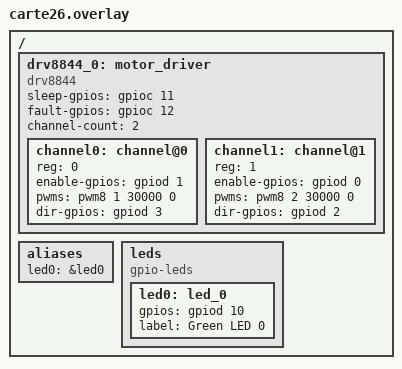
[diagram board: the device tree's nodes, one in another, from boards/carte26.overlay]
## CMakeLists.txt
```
cmake_minimum_required(VERSION 3.13.0)
find_package(Zephyr REQUIRED HINTS $ENV{ZEPHYR_BASE})

project(app LANGUAGES C CXX)
target_sources(app PRIVATE
        src/main.cpp
)
target_include_directories(
        app
        PRIVATE
        include
)
```

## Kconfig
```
# Copyright (c) 2021 Nordic Semiconductor ASA
# SPDX-License-Identifier: Apache-2.0
#
# This file is the application Kconfig entry point. All application Kconfig
# options can be defined here or included via other application Kconfig files.
# You can browse these options using the west targets menuconfig (terminal) or
# guiconfig (GUI).

menu "Zephyr"
source "Kconfig.zephyr"
endmenu

module = APP
module-str = APP
source "subsys/logging/Kconfig.template.log_config"
```

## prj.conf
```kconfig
CONFIG_DRV8876=y
CONFIG_DRV8844=y
CONFIG_PWM=y
CONFIG_CPP=y
CONFIG_STD_CPP20=y
CONFIG_LOG=y
CONFIG_CONSOLE=y
CONFIG_UART_CONSOLE=y
CONFIG_LOG_BACKEND_UART=y
CONFIG_SERIAL=y
CONFIG_LOG_DEFAULT_LEVEL=3
```

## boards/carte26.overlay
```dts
/*
	Created by Awing on the 22/10/2026
	SPDX-License-Identifier: AGPL-3.0
*/

/ {

	drv8844_0: motor_driver {
		compatible = "drv8844";
		status = "okay";

		#address-cells = <1>;
		#size-cells = <0>;

		sleep-gpios = <&gpioc 11 GPIO_ACTIVE_HIGH>;
		fault-gpios = <&gpioc 12 GPIO_ACTIVE_HIGH>;

		channel-count = <2>;

		channel0: channel@0 {
			reg = <0>;
			enable-gpios = <&gpiod 1 GPIO_ACTIVE_HIGH>;
			pwms = <&pwm8 1 30000 0>;
			dir-gpios = <&gpiod 3 GPIO_ACTIVE_HIGH>;
		};

		channel1: channel@1 {
			reg = <1>;
			enable-gpios = <&gpiod 0 GPIO_ACTIVE_HIGH>;
			pwms = <&pwm8 2 30000 0>;
			dir-gpios = <&gpiod 2 GPIO_ACTIVE_HIGH>;
		};

	};

	aliases {
		led0 = &led0;
	};

	leds {
		compatible = "gpio-leds";

		led0: led_0 {
			gpios = <&gpiod 10 GPIO_ACTIVE_HIGH>;
			label = "Green LED 0";
		};
	};

};
```

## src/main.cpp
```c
//
// Created by awing on 10/22/26.
// SPDX-License-Identifier: AGPL-3.0
//


#include <stdio.h>
#include <zephyr/kernel.h>
#include <drivers/crir-motors.h>
#include <zephyr/drivers/gpio.h>
#include <zephyr/logging/log.h>

LOG_MODULE_REGISTER(MAIN, CONFIG_LOG_DEFAULT_LEVEL);

/* 1000 msec = 1 sec */
#define SLEEP_TIME_MS   1000

/* The devicetree node identifier for the "led0" alias. */
#define LED0_NODE DT_ALIAS(led0)

static const struct device * const drv8844 = DEVICE_DT_GET(DT_NODELABEL(drv8844_0));
static const struct gpio_dt_spec led = GPIO_DT_SPEC_GET(LED0_NODE, gpios);

int main() {
    k_sleep(Z_TIMEOUT_MS(1000));
    printk("Starting...");
    if (!device_is_ready(drv8844)) {
        LOG_ERR("DRV8844 is not ready");
        return -1;
    }
    bool led_state = true;

    if (!gpio_is_ready_dt(&led)) {
        return 0;
    }

    int ret = gpio_pin_configure_dt(&led, GPIO_OUTPUT_ACTIVE);
    if (ret < 0) {
        return 0;
    }


    int n = 0;
    while (true) {
        //crir_motors_set_speed(drv8844, 0, static_cast<float>(n) / 10);
        //n++;
        //n %= 11;
        printk("Set speed to %d", n);
        //k_sleep(Z_TIMEOUT_MS(1000));
        ret = gpio_pin_toggle_dt(&led);
        if (ret < 0) {
            return 0;
        }

        led_state = !led_state;
        printf("LED state: %s\n", led_state ? "ON" : "OFF");
        k_sleep(Z_TIMEOUT_MS(1000));
    }

    return 0;
}
```

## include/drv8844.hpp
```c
#pragma once

#include <zephyr/drivers/gpio.h>
#include <zephyr/drivers/pwm.h>

struct Drv8844Motor {
    pwm_dt_spec enable;
    gpio_dt_spec input_a;
    gpio_dt_spec input_b;
};

class Drv8844 {
public:
    Drv8844(const Drv8844Motor& left, const Drv8844Motor& right,
            const gpio_dt_spec& reset, const gpio_dt_spec& fault);

    int init();
    int setVelocity(float left, float right);
    int stop();
    int readFault(bool& faulted) const;

private:
    int setMotor(const Drv8844Motor& motor, float velocity);

    Drv8844Motor left_;
    Drv8844Motor right_;
    gpio_dt_spec reset_;
    gpio_dt_spec fault_;
};
```

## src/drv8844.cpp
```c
#include "drv8844.hpp"

#include <errno.h>

#include <zephyr/device.h>
#include <zephyr/kernel.h>

namespace {
constexpr uint32_t kPwmPeriod = PWM_USEC(50);

bool gpioReady(const gpio_dt_spec& gpio)
{
    return gpio.port != nullptr && device_is_ready(gpio.port);
}
} // namespace

Drv8844::Drv8844(const Drv8844Motor& left, const Drv8844Motor& right,
                 const gpio_dt_spec& reset, const gpio_dt_spec& fault)
    : left_(left), right_(right), reset_(reset), fault_(fault)
{
}

int Drv8844::init()
{
    if (!device_is_ready(left_.enable.dev) ||
        !device_is_ready(right_.enable.dev) ||
        !gpioReady(left_.input_a) || !gpioReady(left_.input_b) ||
        !gpioReady(right_.input_a) || !gpioReady(right_.input_b) ||
        !gpioReady(reset_) || !gpioReady(fault_)) {
        return -ENODEV;
    }

    int ret = gpio_pin_configure_dt(&reset_, GPIO_OUTPUT_ACTIVE);
    if (ret != 0) {
        return ret;
    }

    const Drv8844Motor* motors[] = {&left_, &right_};
    for (const Drv8844Motor* motor : motors) {
        ret = gpio_pin_configure_dt(&motor->input_a, GPIO_OUTPUT_INACTIVE);
        if (ret != 0) {
            return ret;
        }
        ret = gpio_pin_configure_dt(&motor->input_b, GPIO_OUTPUT_INACTIVE);
        if (ret != 0) {
            return ret;
        }
        ret = pwm_set_dt(&motor->enable, kPwmPeriod, 0);
        if (ret != 0) {
            return ret;
        }
    }

    ret = gpio_pin_configure_dt(&fault_, GPIO_INPUT);
    if (ret != 0) {
        return ret;
    }

    return gpio_pin_set_dt(&reset_, 0);
}

int Drv8844::setVelocity(float left, float right)
{
    int ret = setMotor(left_, left);
    if (ret != 0) {
        int stop_ret = stop();
        return stop_ret != 0 ? stop_ret : ret;
    }

    ret = setMotor(right_, right);
    if (ret != 0) {
        int stop_ret = stop();
        return stop_ret != 0 ? stop_ret : ret;
    }
    return ret;
}

int Drv8844::stop()
{
    int left_ret = pwm_set_dt(&left_.enable, kPwmPeriod, 0);
    int right_ret = pwm_set_dt(&right_.enable, kPwmPeriod, 0);
    int left_a_ret = gpio_pin_set_dt(&left_.input_a, 0);
    int left_b_ret = gpio_pin_set_dt(&left_.input_b, 0);
    int right_a_ret = gpio_pin_set_dt(&right_.input_a, 0);
    int right_b_ret = gpio_pin_set_dt(&right_.input_b, 0);

    if (left_ret != 0) return left_ret;
    if (right_ret != 0) return right_ret;
    if (left_a_ret != 0) return left_a_ret;
    if (left_b_ret != 0) return left_b_ret;
    if (right_a_ret != 0) return right_a_ret;
    return right_b_ret;
}

int Drv8844::readFault(bool& faulted) const
{
    int value = gpio_pin_get_dt(&fault_);
    if (value < 0) {
        return value;
    }

    faulted = value != 0;
    return 0;
}

int Drv8844::setMotor(const Drv8844Motor& motor, float velocity)
{
    if (!(velocity >= -1.0f && velocity <= 1.0f)) {
        return -EINVAL;
    }

    float duty = velocity < 0.0f ? -velocity : velocity;
    uint32_t pulse = static_cast<uint32_t>(kPwmPeriod * duty);
    int ret = pwm_set_dt(&motor.enable, kPwmPeriod, 0);
    if (ret != 0) {
        return ret;
    }

    ret = gpio_pin_set_dt(&motor.input_a, velocity > 0.0f);
    if (ret != 0) {
        return ret;
    }
    ret = gpio_pin_set_dt(&motor.input_b, velocity < 0.0f);
    if (ret != 0) {
        return ret;
    }

    return pwm_set_dt(&motor.enable, kPwmPeriod, pulse);
}
```
